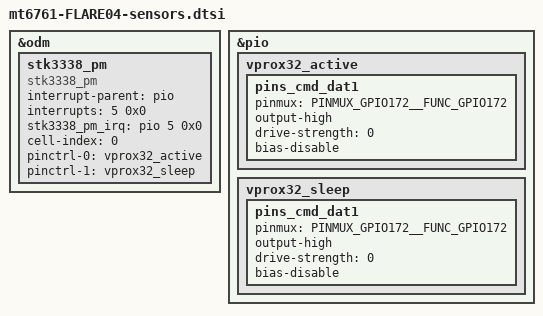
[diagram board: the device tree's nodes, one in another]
/*
 * This software is contributed or developed by KYOCERA Corporation.
 * (C) 2019 KYOCERA Corporation
 * (C) 2020 KYOCERA Corporation
 *
 * This program is free software; you can redistribute it and/or modify
 * it under the terms of the GNU General Public License version 2 and
 * only version 2 as published by the Free Software Foundation.
 *
 * This program is distributed in the hope that it will be useful,
 * but WITHOUT ANY WARRANTY; without even the implied warranty of
 * MERCHANTABILITY or FITNESS FOR A PARTICULAR PURPOSE.  See the
 * GNU General Public License for more details.
 */


&odm {
	stk3338_pm: stk3338_pm {
		interrupt-parent = <&pio>;
		interrupts = <5 0x0>;
		stk3338_pm_irq = <&pio 5 0x0>;

		compatible = "stk3338_pm";
		cell-index = <0>;
		//gpios = <&pio 11 0x0>;  /* STK3338_EN */
		//gpio-names = "STK3338_EN";
		//gpios-func = <0>;
		
		pinctrl-names ="vprox32_active","vprox32_sleep";
		pinctrl-0 = <&vprox32_active>;
		pinctrl-1 = <&vprox32_sleep>;
		status = "okay";
	};
};

&pio {
	vprox32_active: vprox32_active{
         pins_cmd_dat1 {
                        pinmux = <PINMUX_GPIO172__FUNC_GPIO172>;
                        output-high;
                        drive-strength = <0>;
                        bias-disable;
        };
        
	};

	vprox32_sleep: vprox32_sleep{
         pins_cmd_dat1 {
                        pinmux = <PINMUX_GPIO172__FUNC_GPIO172>;
                        output-high;
                        drive-strength = <0>;
                        bias-disable;
        };
	};
};
